AUTOSAR XML (schema 4-0-3)
standard types defined: UInt32, UInt8
package /AUTOSAR_Platform/DataConstrs
  range DC_UInt8: raw 0..255
package /PATAC/MSM/ComponentTypes
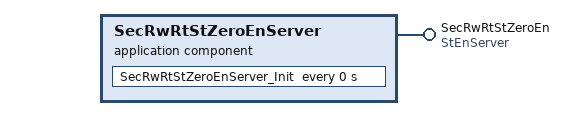
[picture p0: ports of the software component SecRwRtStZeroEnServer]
  application sw component type SecRwRtStZeroEnServer
    provide port SecRwRtStZeroEn: provided-com-specs=[{operation=Clear, queue-length=1}, {operation=Get, queue-length=1}, {operation=Set, queue-length=1}], provided-interface=StEnServer
    behavior SecRwRtStZeroEnServer_InternalBehavior
      operation invoked event OIT_SecRwRtStZeroEn_Clear_SecRwRtStZeroEn_Clear: start-on-event=SecRwRtStZeroEn_Clear, operation=SecRwRtStZeroEn.Clear
      operation invoked event OIT_SecRwRtStZeroEn_Get_SecRwRtStZeroEn_Get: start-on-event=SecRwRtStZeroEn_Get, operation=SecRwRtStZeroEn.Get
      operation invoked event OIT_SecRwRtStZeroEn_Set_SecRwRtStZeroEn_Set: start-on-event=SecRwRtStZeroEn_Set, operation=SecRwRtStZeroEn.Set
      timing event SecRwLtStZeroEnServer_InitEvent: start-on-event=SecRwRtStZeroEnServer_Init, period=0
      4 x runnable:
        SecRwRtStZeroEn_Clear
        SecRwRtStZeroEn_Get
        SecRwRtStZeroEn_Set
        SecRwRtStZeroEnServer_Init
  swc implementation SecRwRtStZeroEnServer_Implementation: behavior=SecRwRtStZeroEnServer_InternalBehavior
    code-descriptors:
      code Default: artifact-descriptors=autosar-engineering-object={short-label=Default, category=SWSRC}
package /PATAC/MSM/ModeAdjust/PortInterface
  client server interface StEnServer
    operation Clear
      arg data: type=UInt8, direction=IN, server-argument-impl-policy=USE-ARGUMENT-TYPE
    operation Get
      arg data: type=UInt32, direction=OUT, server-argument-impl-policy=USE-ARGUMENT-TYPE
    operation Set
      arg data: type=UInt8, direction=IN, server-argument-impl-policy=USE-ARGUMENT-TYPE
